# AE512F80F5582AS_CM55_HE_View register map
Vendor: Alif Semiconductor; Series: E5; File version: 1.0
CPU: CM55 r1p0, selectable endian, MPU, FPU, double-precision FPU, DSP, VTOR, 8 interrupt priority bits, 1 SAU regions
Registers are 32-bit, read-write, reset 0x0 unless marked. A register's access mark holds for its fields unless they carry their own. Offsets are from the block's base; [hi:lo] are bit positions; 'fields as' and 'values as' point back to an identical list.

## CLKCTL_SYS
Base 0x1A010000
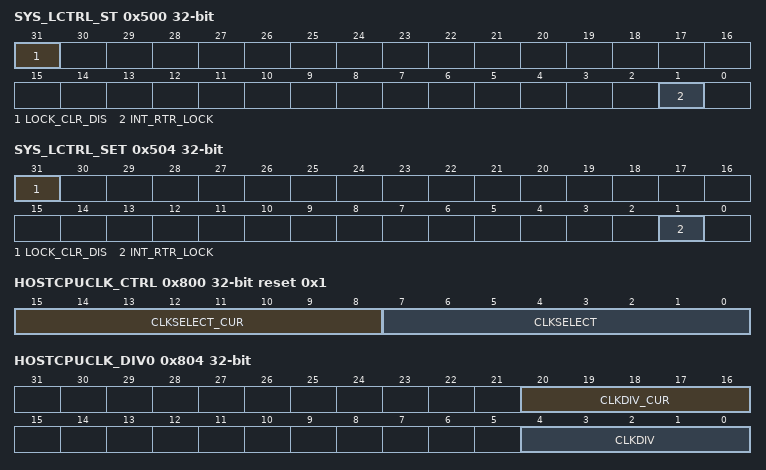
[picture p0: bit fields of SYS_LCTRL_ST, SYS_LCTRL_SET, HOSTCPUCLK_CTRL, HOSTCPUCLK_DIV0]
0x500 SYS_LCTRL_ST ro — System Lock Control Status Register
  [31] LOCK_CLR_DIS — SYS_LCTRL_CLR register behavior indicator
    0=Writes to the SYS_LCTRL_CLR register take effect; 1=Writes to the SYS_LCTRL_CLR register are ignored
  [1] INT_RTR_LOCK — IRQRTR lockdown interface indicator
    0=IRQRTR lockdown interface is de-asserted; 1=IRQRTR lockdown interface is asserted
0x504 SYS_LCTRL_SET — System Lock Control Set Register
  [31] LOCK_CLR_DIS wo — Writing 0x1 to this bit sets the SYS_LCTRL_ST[LOCK_CLR_DIS] bit to 0x1 Writing 0x0 to this bit has no effect on the value of the SYS_LCTRL_ST[LOCK_CLR_DIS] bit This bit always reads as 0x0
  [1] INT_RTR_LOCK wo — Writing 0x1 to this bit sets the SYS_LCTRL_ST[INT_RTR_LOCK] bit to 0x1 Writing 0x0 to this bit has no effect on the value of the SYS_LCTRL_ST[INT_RTR_LOCK] bit This bit always reads as 0x0
0x508 SYS_LCTRL_CLR — System Lock Control Clear Register
  [1] INT_RTR_LOCK wo — Writing 0x1 to this bit sets the SYS_LCTRL_ST[INT_RTR_LOCK] bit to 0x0 Writing 0x0 to this bit has no effect on the value of the SYS_LCTRL_ST[INT_RTR_LOCK] bit This bit always reads as 0x0
0x800 HOSTCPUCLK_CTRL reset 0x1 (reset mask 0xFFFF00FF) — APSS_CLK Clock Control Register
  [15:8] CLKSELECT_CUR ro — Currently selected clock source for APSS_CLK All other values are reserved.
    0=Clock gated; 1=SYST_REFCLK; 2=SYSPLL_CLK divided by HOSTCPUCLK_DIV1[CLKDIV]; 4=CPUPLL_CLK divided by HOSTCPUCLK_DIV0[CLKDIV]
  [7:0] CLKSELECT — Select the clock source for APSS_CLK All other values are reserved. Selecting a reserved value can cause a deadlock.
    values as CLKSELECT_CUR
0x804 HOSTCPUCLK_DIV0 (reset mask 0xFFE0FFFF) — APSS_CLK Clock Divider 0 Register
  [20:16] CLKDIV_CUR ro — Current value of integer divider applied to SYSPLL_CLK
    0=Divided by 1; 1=Divided by 2; 31=Divided by 32
  [4:0] CLKDIV — Select the value of the integer divider applied to SYSPLL_CLK
    0=Divide by 1; 1=Divide by 2; 31=Divide by 32
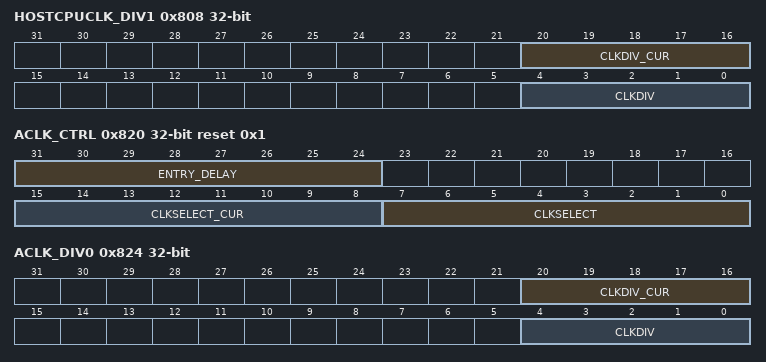
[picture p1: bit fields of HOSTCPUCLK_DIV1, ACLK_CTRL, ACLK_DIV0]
0x808 HOSTCPUCLK_DIV1 (reset mask 0xFFE0FFFF) — APSS_CLK Clock Divider 1 Register
  [20:16] CLKDIV_CUR ro — Current value of integer divider applied to CPUPLL_CLK
    0=Divided by 1; 1=Divided by 2; 31=Divided by 32
  [4:0] CLKDIV — Select the value of the integer divider applied to CPUPLL_CLK
    0=Divide by 1; 1=Divide by 2; 31=Divide by 32
0x820 ACLK_CTRL reset 0x1 (reset mask 0xFFFF00FF) — SYST_ACLK Clock Control Register
  [31:24] ENTRY_DELAY — Configure number of idle clock cycles before clock is gated.
  [15:8] CLKSELECT_CUR ro — Currently selected clock source for SYST_ACLK All other values are reserved.
    0=Clock gated; 1=SYST_REFCLK; 2=SYSPLL_CLK divided by ACLK_DIV0[CLKDIV]
  [7:0] CLKSELECT — Select the clock source for SYST_ACLK All other values are reserved. Selecting a reserved value can cause a deadlock.
    values as CLKSELECT_CUR
0x824 ACLK_DIV0 (reset mask 0xFFE0FFFF) — SYST_ACLK Clock Divider 0 Register
  fields as HOSTCPUCLK_DIV0

## REFCLK_CNTControl
Base 0x1A200000
Same registers: S32K_CNTControl 0x1A400000
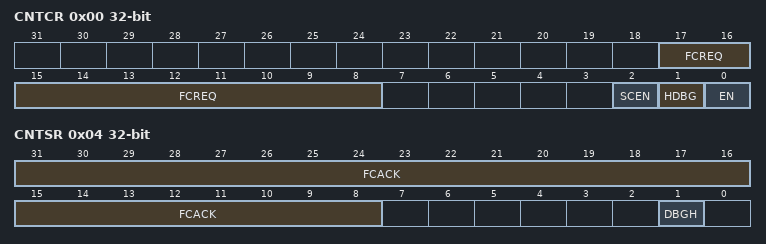
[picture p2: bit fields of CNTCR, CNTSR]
0x00 CNTCR (reset mask 0xFFFFFFF9) — Counter Control Register
  [17:8] FCREQ — Frequency change request. Specifies the index of the CNTFIDn register that holds the counter new frequency. Changing the value of this field requests a change to the counter update frequency. Any non-required most-significant bits are read-only and reserved.
  [2] SCEN — Scale Enable. This bit can only be changed when the counter is disabled (when CNTCR[EN] = 0x0). If the value of CNTCR[SCEN] changes when CNTCR[EN] = 0x1 then the counter value becomes unknown and remains unknown on future ticks of the clock.
    0=Scaling disabled. The counter value is incremented by 0x1 for each counter tick.; 1=Scaling enabled. The counter value is incremented by CNTSCR[SCALEVAL] for each counter tick.
  [1] HDBG — Halt-on-debug. Controls whether a halt-on-debug request halts the system counter.
    0=The counter ignores the halt-on-debug request; 1=When the halt-on-debug request is activated the counter halts
  [0] EN — Counter enable.
    0=System counter disabled; 1=System counter enabled
0x04 CNTSR ro (reset mask 0xFFFFFFFD) — Counter Status Register
  [31:8] FCACK — Frequency change acknowledge. Specifies the index of the CNTFIDn register that holds the counter new frequency.
  [1] DBGH — Indicates whether the counter is halted because of a halt-on-debug request.
    0=Counter is not halted; 1=Counter is halted
0x08 CNTCVL reset not defined — Counter Count Value Low Register
  [31:0] COUNTVALUE_LO — Bits [31:0] of the current counter value.
0x0C CNTCVH reset not defined — Counter Count Value High Register
  [31:0] COUNTVALUE_HI — Bits [63:32] of the current counter value.
